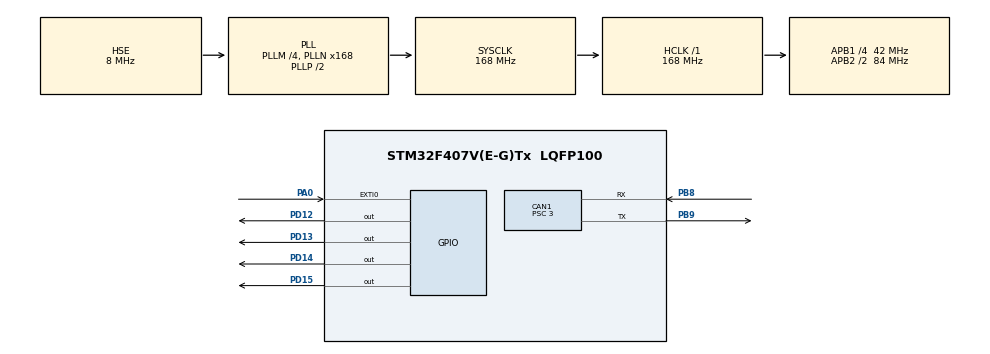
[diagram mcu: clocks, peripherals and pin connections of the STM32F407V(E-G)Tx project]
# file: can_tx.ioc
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CAN1.BS1=CAN_BS1_11TQ
CAN1.BS2=CAN_BS2_2TQ
CAN1.CalculateBaudRate=1000000
CAN1.CalculateTimeBit=1000
CAN1.CalculateTimeQuantum=71.42857142857143
CAN1.Prescaler=3
Mcu.Family=STM32F4
Mcu.Name=STM32F407V(E-G)Tx
Mcu.Package=LQFP100
NVIC.CAN1_RX0_IRQn=true\:0\:0\:false\:false\:true\:true\:true\:true
NVIC.CAN1_SCE_IRQn=true\:0\:0\:false\:false\:true\:true\:true\:true
NVIC.CAN1_TX_IRQn=true\:0\:0\:false\:false\:true\:true\:true\:true
NVIC.EXTI0_IRQn=true\:0\:0\:false\:false\:true\:true\:true\:true
NVIC.PriorityGroup=NVIC_PRIORITYGROUP_0
NVIC.TIM1_BRK_TIM9_IRQn=true\:0\:0\:false\:false\:true\:true\:true\:true
PA0-WKUP.Signal=GPXTI0
PA13.Mode=Serial_Wire
PA13.Signal=SYS_JTMS-SWDIO
PA14.Mode=Serial_Wire
PA14.Signal=SYS_JTCK-SWCLK
PB8.Mode=CAN_Activate
PB8.Signal=CAN1_RX
PB9.Mode=CAN_Activate
PB9.Signal=CAN1_TX
PD12.Signal=GPIO_Output
PD13.Signal=GPIO_Output
PD14.Signal=GPIO_Output
PD15.Signal=GPIO_Output
PH0-OSC_IN.Mode=HSE-External-Oscillator
PH0-OSC_IN.Signal=RCC_OSC_IN
PH1-OSC_OUT.Mode=HSE-External-Oscillator
PH1-OSC_OUT.Signal=RCC_OSC_OUT
ProjectManager.HeapSize=0x200
ProjectManager.StackSize=0x400
ProjectManager.TargetToolchain=MDK-ARM V5.32
RCC.48MHZClocksFreq_Value=48000000
RCC.AHBFreq_Value=168000000
RCC.APB1CLKDivider=RCC_HCLK_DIV4
RCC.APB1Freq_Value=42000000
RCC.APB1TimFreq_Value=84000000
RCC.APB2CLKDivider=RCC_HCLK_DIV2
RCC.APB2Freq_Value=84000000
RCC.APB2TimFreq_Value=168000000
RCC.CortexFreq_Value=168000000
RCC.HCLKFreq_Value=168000000
RCC.HSE_VALUE=8000000
RCC.HSI_VALUE=16000000
RCC.LSE_VALUE=32768
RCC.PLLM=4
RCC.PLLN=168
RCC.PLLQ=7
RCC.PLLSourceVirtual=RCC_PLLSOURCE_HSE
RCC.SYSCLKFreq_VALUE=168000000
RCC.SYSCLKSource=RCC_SYSCLKSOURCE_PLLCLK
RCC.VCOOutputFreq_Value=336000000
TIM9.Period=9999
VP_TIM9_VS_ClockSourceINT.Mode=Internal
board=STM32F407G-DISC1

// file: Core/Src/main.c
#include "main.h"

CAN_HandleTypeDef hcan1;

TIM_HandleTypeDef htim9;

void SystemClock_Config(void);
static void MX_GPIO_Init(void);
static void MX_CAN1_Init(void);
static void MX_TIM9_Init(void);

CAN_TxHeaderTypeDef txHeader;
CAN_RxHeaderTypeDef rxHeader;

uint8_t txData[8];
uint8_t rxData[8];

uint32_t txMailbox;
int data_check = 1;

void ___ROM_EXTI0_IRQHandler(void)
{
	//if( __HAL_GPIO_EXTI_GET_FLAG(GPIO_PIN_0) != RESET )

		if(data_check > 5 ) { data_check = 1; }

		txData[0] = data_check++;

		HAL_CAN_AddTxMessage(&hcan1, &txHeader, txData, &txMailbox);

		__HAL_GPIO_EXTI_CLEAR_FLAG(GPIO_PIN_0);

}

void HAL_CAN_RxFifo0MsgPendingCallback(CAN_HandleTypeDef *hcan)
{
	//HAL_CAN_GetRxMessage(hcan, CAN_RX_FIFO0, &rxHeader, rxData);

}
//---------------------------------------------- rom end
int main(void)
{
  HAL_Init();

  SystemClock_Config();

  MX_GPIO_Init();
  MX_CAN1_Init();
  MX_TIM9_Init();

	//---------------------------------------------------------------
	HAL_CAN_Start(&hcan1);
	HAL_CAN_ActivateNotification(&hcan1,CAN_IT_RX_FIFO0_MSG_PENDING);

	txHeader.DLC = 1; // data length
	txHeader.IDE = CAN_ID_STD;
	txHeader.RTR = CAN_RTR_DATA;
	txHeader.StdId = 0x446; // ID

  while (1)
  {/*
		if(data_check)
		{
			for(int i=0;i<rxData[1];i++)
			{
				HAL_GPIO_TogglePin(GPIOD,GPIO_PIN_12 | GPIO_PIN_13 | GPIO_PIN_14 | GPIO_PIN_15);
				HAL_Delay(rxData[0]);
			}
			data_check = 0;
		}
		*/
  }

}

void SystemClock_Config(void)
{
  RCC_OscInitTypeDef RCC_OscInitStruct = {0};
  RCC_ClkInitTypeDef RCC_ClkInitStruct = {0};

  /** Configure the main internal regulator output voltage
  */
  __HAL_RCC_PWR_CLK_ENABLE();
  __HAL_PWR_VOLTAGESCALING_CONFIG(PWR_REGULATOR_VOLTAGE_SCALE1);

  /** Initializes the RCC Oscillators according to the specified parameters
  * in the RCC_OscInitTypeDef structure.
  */
  RCC_OscInitStruct.OscillatorType = RCC_OSCILLATORTYPE_HSE;
  RCC_OscInitStruct.HSEState = RCC_HSE_ON;
  RCC_OscInitStruct.PLL.PLLState = RCC_PLL_ON;
  RCC_OscInitStruct.PLL.PLLSource = RCC_PLLSOURCE_HSE;
  RCC_OscInitStruct.PLL.PLLM = 4;
  RCC_OscInitStruct.PLL.PLLN = 168;
  RCC_OscInitStruct.PLL.PLLP = RCC_PLLP_DIV2;
  RCC_OscInitStruct.PLL.PLLQ = 7;
  if (HAL_RCC_OscConfig(&RCC_OscInitStruct) != HAL_OK)
  {
    Error_Handler();
  }

  /** Initializes the CPU, AHB and APB buses clocks
  */
  RCC_ClkInitStruct.ClockType = RCC_CLOCKTYPE_HCLK|RCC_CLOCKTYPE_SYSCLK
                              |RCC_CLOCKTYPE_PCLK1|RCC_CLOCKTYPE_PCLK2;
  RCC_ClkInitStruct.SYSCLKSource = RCC_SYSCLKSOURCE_PLLCLK;
  RCC_ClkInitStruct.AHBCLKDivider = RCC_SYSCLK_DIV1;
  RCC_ClkInitStruct.APB1CLKDivider = RCC_HCLK_DIV4;
  RCC_ClkInitStruct.APB2CLKDivider = RCC_HCLK_DIV2;

  if (HAL_RCC_ClockConfig(&RCC_ClkInitStruct, FLASH_LATENCY_5) != HAL_OK)
  {
    Error_Handler();
  }
}

static void MX_CAN1_Init(void)
{
  hcan1.Instance = CAN1;
  hcan1.Init.Prescaler = 3;
  hcan1.Init.Mode = CAN_MODE_NORMAL;
  hcan1.Init.SyncJumpWidth = CAN_SJW_1TQ;
  hcan1.Init.TimeSeg1 = CAN_BS1_11TQ;
  hcan1.Init.TimeSeg2 = CAN_BS2_2TQ;
  hcan1.Init.TimeTriggeredMode = DISABLE;
  hcan1.Init.AutoBusOff = DISABLE;
  hcan1.Init.AutoWakeUp = DISABLE;
  hcan1.Init.AutoRetransmission = DISABLE;
  hcan1.Init.ReceiveFifoLocked = DISABLE;
  hcan1.Init.TransmitFifoPriority = DISABLE;

  if (HAL_CAN_Init(&hcan1) != HAL_OK)
  {
    Error_Handler();
  }
  /* USER CODE BEGIN CAN1_Init 2 */
	CAN_FilterTypeDef can1_filter;

	can1_filter.FilterActivation = ENABLE;
	can1_filter.FilterBank = 0;
	can1_filter.FilterFIFOAssignment = CAN_RX_FIFO0;
	can1_filter.FilterIdHigh = 0x0000;
	can1_filter.FilterIdLow = 0x0000;
	can1_filter.FilterMaskIdHigh = 0x0000;
	can1_filter.FilterMaskIdLow = 0x0000;
	can1_filter.FilterMode = CAN_FILTERMODE_IDMASK;
	can1_filter.FilterScale = CAN_FILTERSCALE_32BIT;
	//can1_filter.SlaveStartFilterBank = 0;

	HAL_CAN_ConfigFilter(&hcan1, &can1_filter);
  /* USER CODE END CAN1_Init 2 */

}

static void MX_TIM9_Init(void)
{

  TIM_ClockConfigTypeDef sClockSourceConfig = {0};

  htim9.Instance = TIM9;
  htim9.Init.Prescaler = 0;
  htim9.Init.CounterMode = TIM_COUNTERMODE_UP;
  htim9.Init.Period = 9999;
  htim9.Init.ClockDivision = TIM_CLOCKDIVISION_DIV1;
  htim9.Init.AutoReloadPreload = TIM_AUTORELOAD_PRELOAD_DISABLE;
  if (HAL_TIM_Base_Init(&htim9) != HAL_OK)
  {
    Error_Handler();
  }
  sClockSourceConfig.ClockSource = TIM_CLOCKSOURCE_INTERNAL;
  if (HAL_TIM_ConfigClockSource(&htim9, &sClockSourceConfig) != HAL_OK)
  {
    Error_Handler();
  }

}

static void MX_GPIO_Init(void)
{
  GPIO_InitTypeDef GPIO_InitStruct = {0};

  /* GPIO Ports Clock Enable */
  __HAL_RCC_GPIOH_CLK_ENABLE();
  __HAL_RCC_GPIOA_CLK_ENABLE();
  __HAL_RCC_GPIOD_CLK_ENABLE();
  __HAL_RCC_GPIOB_CLK_ENABLE();

  /*Configure GPIO pin Output Level */
  HAL_GPIO_WritePin(GPIOD, GPIO_PIN_12|GPIO_PIN_13|GPIO_PIN_14|GPIO_PIN_15, GPIO_PIN_RESET);

  /*Configure GPIO pin : PA0 */
  GPIO_InitStruct.Pin = GPIO_PIN_0;
  GPIO_InitStruct.Mode = GPIO_MODE_IT_RISING;
  GPIO_InitStruct.Pull = GPIO_NOPULL;
  HAL_GPIO_Init(GPIOA, &GPIO_InitStruct);

  /*Configure GPIO pins : PD12 PD13 PD14 PD15 */
  GPIO_InitStruct.Pin = GPIO_PIN_12|GPIO_PIN_13|GPIO_PIN_14|GPIO_PIN_15;
  GPIO_InitStruct.Mode = GPIO_MODE_OUTPUT_PP;
  GPIO_InitStruct.Pull = GPIO_NOPULL;
  GPIO_InitStruct.Speed = GPIO_SPEED_FREQ_LOW;
  HAL_GPIO_Init(GPIOD, &GPIO_InitStruct);

  /* EXTI interrupt init*/
  HAL_NVIC_SetPriority(EXTI0_IRQn, 0, 0);
  HAL_NVIC_EnableIRQ(EXTI0_IRQn);

}

void Error_Handler(void)
{
  __disable_irq();
  while (1)
  {
  }
}
